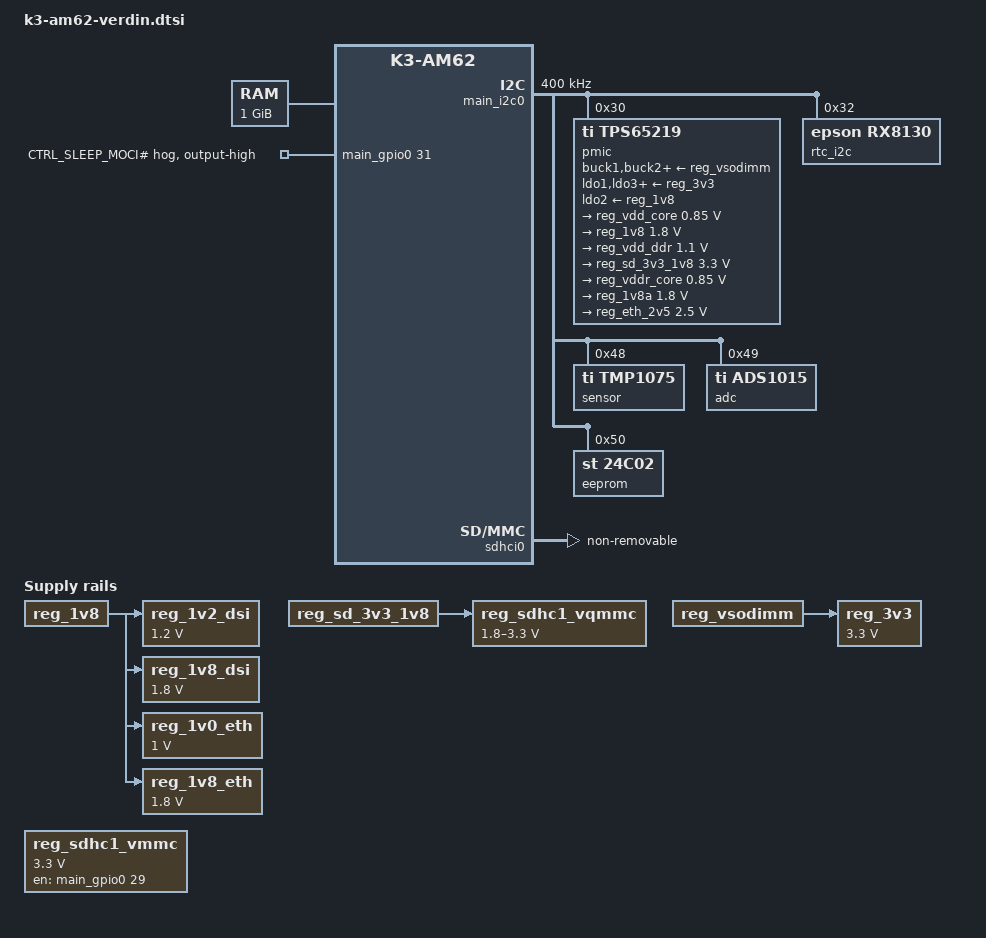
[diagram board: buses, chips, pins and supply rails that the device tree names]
#include <dt-bindings/gpio/gpio.h>
#include <dt-bindings/input/input.h>
#include <dt-bindings/interrupt-controller/arm-gic.h>
#include <dt-bindings/interrupt-controller/irq.h>
#include <dt-bindings/net/ti-dp83867.h>
/ {
	chosen {
		stdout-path = "serial2:115200n8";
	};
	aliases {
		can0 = &main_mcan0;
		can1 = &mcu_mcan0;
		ethernet0 = &cpsw_port1;
		ethernet1 = &cpsw_port2;
		i2c0 = &main_i2c0;
		i2c1 = &main_i2c1;
		i2c2 = &main_i2c2;
		i2c3 = &mcu_i2c0;
		i2c4 = &main_i2c3;
		mmc0 = &sdhci0;
		mmc1 = &sdhci1;
		mmc2 = &sdhci2;
		rtc0 = &rtc_i2c;
		rtc1 = &wkup_rtc0;
		serial0 = &main_uart1;
		serial1 = &wkup_uart0;
		serial2 = &main_uart0;
		serial3 = &mcu_uart0;
		serial4 = &main_uart5;
		usb0 = &usb0;
		usb1 = &usb1;
	};
	verdin_gpio_keys: gpio-keys {
		compatible = "gpio-keys";
		pinctrl-names = "default";
		pinctrl-0 = <&pinctrl_ctrl_wake1_mico>;
		status = "disabled";
		verdin_key_wakeup: key-wakeup {
			debounce-interval = <10>;
			gpios = <&main_gpio0 32 GPIO_ACTIVE_LOW>;
			label = "Wake-Up";
			linux,code = <KEY_WAKEUP>;
			wakeup-source;
		};
	};
	memory@80000000 {
		device_type = "memory";
		reg = <0x00000000 0x80000000 0x00000000 0x40000000>;  
	};
	opp-table {
		opp-1400000000 {
			opp-hz = /bits/ 64 <1400000000>;
			opp-supported-hw = <0x01 0x0004>;
			clock-latency-ns = <6000000>;
		};
	};
	reg_vsodimm: regulator-vsodimm {
		compatible = "regulator-fixed";
		regulator-name = "+V_SODIMM";
	};
	reg_3v3: regulator-3v3 {
		compatible = "regulator-fixed";
		regulator-max-microvolt = <3300000>;
		regulator-min-microvolt = <3300000>;
		regulator-name = "On-module +V3.3";
		vin-supply = <&reg_vsodimm>;
	};
	reg_1v2_dsi: regulator-1v2-dsi {
		compatible = "regulator-fixed";
		regulator-max-microvolt = <1200000>;
		regulator-min-microvolt = <1200000>;
		regulator-name = "On-module +V1.2_DSI";
		vin-supply = <&reg_1v8>;
	};
	reg_1v8_dsi: regulator-1v8-dsi {
		compatible = "regulator-fixed";
		regulator-max-microvolt = <1800000>;
		regulator-min-microvolt = <1800000>;
		regulator-name = "On-module +V1.8_DSI";
		vin-supply = <&reg_1v8>;
	};
	reg_1v0_eth: regulator-1v0-eth {
		compatible = "regulator-fixed";
		regulator-max-microvolt = <1000000>;
		regulator-min-microvolt = <1000000>;
		regulator-name = "On-module +V1.0_ETH";
		vin-supply = <&reg_1v8>;
	};
	reg_1v8_eth: regulator-1v8-eth {
		compatible = "regulator-fixed";
		regulator-max-microvolt = <1800000>;
		regulator-min-microvolt = <1800000>;
		regulator-name = "On-module +V1.8_ETH";
		vin-supply = <&reg_1v8>;
	};
	reg_sdhc1_vmmc: regulator-sdhci1 {
		compatible = "regulator-fixed";
		pinctrl-names = "default";
		pinctrl-0 = <&pinctrl_sd1_pwr_en>;
		enable-active-high;
		gpio = <&main_gpio0 29 GPIO_ACTIVE_HIGH>;
		off-on-delay-us = <100000>;
		regulator-max-microvolt = <3300000>;
		regulator-min-microvolt = <3300000>;
		regulator-name = "+V3.3_SD";
		startup-delay-us = <2000>;
	};
	reg_sdhc1_vqmmc: regulator-sdhci1-vqmmc {
		compatible = "regulator-gpio";
		pinctrl-names = "default";
		pinctrl-0 = <&pinctrl_vsel_sd>;
		gpios = <&main_gpio0 21 GPIO_ACTIVE_HIGH>;
		regulator-name = "LDO1-VSEL-SD (PMIC)";
		regulator-min-microvolt = <1800000>;
		regulator-max-microvolt = <3300000>;
		states = <1800000 0x0>,
			 <3300000 0x1>;
		vin-supply = <&reg_sd_3v3_1v8>;
	};
	reserved-memory {
		#address-cells = <2>;
		#size-cells = <2>;
		ranges;
		secure_tfa_ddr: tfa@9e780000 {
			reg = <0x00 0x9e780000 0x00 0x80000>;
			alignment = <0x1000>;
			no-map;
		};
		secure_ddr: optee@9e800000 {
			reg = <0x00 0x9e800000 0x00 0x01800000>;  
			alignment = <0x1000>;
			no-map;
		};
		wkup_r5fss0_core0_dma_memory_region: r5f-dma-memory@9db00000 {
			compatible = "shared-dma-pool";
			reg = <0x00 0x9db00000 0x00 0xc00000>;
			no-map;
		};
	};
};
&main_pmx0 {
	pinctrl_epwm0_a: main-epwm0a-default-pins {
		pinctrl-single,pins = <
			AM62X_IOPAD(0x01b4, PIN_OUTPUT, 2)    
		>;
	};
	pinctrl_epwm0_b: main-epwm0b-default-pins {
		pinctrl-single,pins = <
			AM62X_IOPAD(0x01b8, PIN_OUTPUT, 2)    
		>;
	};
	pinctrl_epwm1_a: main-epwm1a-default-pins {
		pinctrl-single,pins = <
			AM62X_IOPAD(0x01bc, PIN_OUTPUT, 2)    
		>;
	};
	pinctrl_qspi1_clk_gpio: main-gpio0-0-default-pins {
		pinctrl-single,pins = <
			AM62X_IOPAD(0x0000, PIN_INPUT, 7)    
		>;
	};
	pinctrl_qspi1_io0_gpio: main-gpio0-3-default-pins {
		pinctrl-single,pins = <
			AM62X_IOPAD(0x000c, PIN_INPUT, 7)    
		>;
	};
	pinctrl_qspi1_io1_gpio: main-gpio0-4-default-pins {
		pinctrl-single,pins = <
			AM62X_IOPAD(0x0010, PIN_INPUT, 7)    
		>;
	};
	pinctrl_qspi1_io2_gpio: main-gpio0-5-default-pins {
		pinctrl-single,pins = <
			AM62X_IOPAD(0x0014, PIN_INPUT, 7)    
		>;
	};
	pinctrl_qspi1_io3_gpio: main-gpio0-6-default-pins {
		pinctrl-single,pins = <
			AM62X_IOPAD(0x0018, PIN_INPUT, 7)    
		>;
	};
	pinctrl_qspi1_cs_gpio: main-gpio0-11-default-pins {
		pinctrl-single,pins = <
			AM62X_IOPAD(0x002c, PIN_INPUT, 7)    
		>;
	};
	pinctrl_qspi1_cs2_gpio: main-gpio0-12-default-pins {
		pinctrl-single,pins = <
			AM62X_IOPAD(0x0030, PIN_INPUT, 7)    
		>;
	};
	pinctrl_wifi_w_wkup_host: main-gpio0-15-default-pins {
		pinctrl-single,pins = <
			AM62X_IOPAD(0x003c, PIN_INPUT, 7)    
		>;
	};
	pinctrl_bt_wkup_host: main-gpio0-16-default-pins {
		pinctrl-single,pins = <
			AM62X_IOPAD(0x0040, PIN_INPUT, 7)    
		>;
	};
	pinctrl_eth_reset: main-gpio0-17-default-pins {
		pinctrl-single,pins = <
			AM62X_IOPAD(0x0044, PIN_INPUT, 7)  
		>;
	};
	pinctrl_bridge_reset: main-gpio0-20-default-pins {
		pinctrl-single,pins = <
			AM62X_IOPAD(0x0050, PIN_INPUT, 7)  
		>;
	};
	pinctrl_vsel_sd: main-gpio0-21-default-pins {
		pinctrl-single,pins = <
			AM62X_IOPAD(0x0054, PIN_INPUT, 7)  
		>;
	};
	pinctrl_wifi_en: main-gpio0-22-default-pins {
		pinctrl-single,pins = <
			AM62X_IOPAD(0x0058, PIN_INPUT, 7)  
		>;
	};
	pinctrl_eth_int: main-gpio0-25-default-pins {
		pinctrl-single,pins = <
			AM62X_IOPAD(0x0064, PIN_INPUT_PULLUP, 7)  
		>;
	};
	pinctrl_wifi_wkup_bt: main-gpio0-26-default-pins {
		pinctrl-single,pins = <
			AM62X_IOPAD(0x0068, PIN_INPUT, 7)  
		>;
	};
	pinctrl_wifi_wkup_wlan: main-gpio0-27-default-pins {
		pinctrl-single,pins = <
			AM62X_IOPAD(0x006c, PIN_INPUT, 7)  
		>;
	};
	pinctrl_sd1_pwr_en: main-gpio0-29-default-pins {
		pinctrl-single,pins = <
			AM62X_IOPAD(0x0074, PIN_INPUT, 7)    
		>;
	};
	pinctrl_dsi1_bkl_en: main-gpio0-30-default-pins {
		pinctrl-single,pins = <
			AM62X_IOPAD(0x0078, PIN_INPUT, 7)    
		>;
	};
	pinctrl_ctrl_sleep_moci: main-gpio0-31-default-pins {
		pinctrl-single,pins = <
			AM62X_IOPAD(0x007c, PIN_INPUT, 7)    
		>;
	};
	pinctrl_ctrl_wake1_mico: main-gpio0-32-default-pins {
		pinctrl-single,pins = <
			AM62X_IOPAD(0x0084, PIN_INPUT_PULLUP, 7)    
		>;
	};
	pinctrl_i2s_2_d_out_gpio: main-gpio0-34-default-pins {
		pinctrl-single,pins = <
			AM62X_IOPAD(0x008c, PIN_INPUT, 7)    
		>;
	};
	pinctrl_i2s_2_bclk_gpio: main-gpio0-35-default-pins {
		pinctrl-single,pins = <
			AM62X_IOPAD(0x0090, PIN_INPUT, 7)    
		>;
	};
	pinctrl_gpio_6: main-gpio0-36-default-pins {
		pinctrl-single,pins = <
			AM62X_IOPAD(0x0094, PIN_INPUT, 7)    
		>;
	};
	pinctrl_eth2_rgmii_int: main-gpio0-38-default-pins {
		pinctrl-single,pins = <
			AM62X_IOPAD(0x009c, PIN_INPUT, 7)    
		>;
	};
	pinctrl_gpio_5: main-gpio0-40-default-pins {
		pinctrl-single,pins = <
			AM62X_IOPAD(0x00a4, PIN_INPUT, 7)    
		>;
	};
	pinctrl_gpio_7: main-gpio0-41-default-pins {
		pinctrl-single,pins = <
			AM62X_IOPAD(0x00a8, PIN_INPUT, 7)    
		>;
	};
	pinctrl_gpio_8: main-gpio0-42-default-pins {
		pinctrl-single,pins = <
			AM62X_IOPAD(0x00ac, PIN_INPUT, 7)    
		>;
	};
	pinctrl_usb1_oc: main-gpio0-71-default-pins {
		pinctrl-single,pins = <
			AM62X_IOPAD(0x0124, PIN_INPUT, 7)    
		>;
	};
	pinctrl_usb2_oc: main-gpio0-72-default-pins {
		pinctrl-single,pins = <
			AM62X_IOPAD(0x0128, PIN_INPUT, 7)    
		>;
	};
	pinctrl_pwm3_dsi_gpio: main-gpio1-17-default-pins {
		pinctrl-single,pins = <
			AM62X_IOPAD(0x01bc, PIN_INPUT, 7)    
		>;
	};
	pinctrl_qspi1_dqs_gpio: main-gpio1-18-default-pins {
		pinctrl-single,pins = <
			AM62X_IOPAD(0x01c0, PIN_INPUT, 7)    
		>;
	};
	pinctrl_usb0_id: main-gpio1-19-default-pins {
		pinctrl-single,pins = <
			AM62X_IOPAD(0x01c4, PIN_INPUT, 7)    
		>;
	};
	pinctrl_dsi1_int: main-gpio1-49-default-pins {
		pinctrl-single,pins = <
			AM62X_IOPAD(0x0244, PIN_INPUT_PULLUP, 7)    
		>;
	};
	pinctrl_i2c0: main-i2c0-default-pins {
		pinctrl-single,pins = <
			AM62X_IOPAD(0x01e0, PIN_INPUT, 0)    
			AM62X_IOPAD(0x01e4, PIN_INPUT, 0)    
		>;
	};
	pinctrl_i2c1: main-i2c1-default-pins {
		pinctrl-single,pins = <
			AM62X_IOPAD(0x01e8, PIN_INPUT_PULLUP, 0)    
			AM62X_IOPAD(0x01ec, PIN_INPUT_PULLUP, 0)    
		>;
	};
	pinctrl_i2c2: main-i2c2-default-pins {
		pinctrl-single,pins = <
			AM62X_IOPAD(0x00b0, PIN_INPUT, 1)    
			AM62X_IOPAD(0x00b4, PIN_INPUT, 1)    
		>;
	};
	pinctrl_i2c3: main-i2c3-default-pins {
		pinctrl-single,pins = <
			AM62X_IOPAD(0x01d0, PIN_INPUT, 2)    
			AM62X_IOPAD(0x01d4, PIN_INPUT, 2)    
		>;
	};
	pinctrl_i2s1_mclk: main-system-audio-ext-reflock1-default-pins {
		pinctrl-single,pins = <
			AM62X_IOPAD(0x00a0, PIN_OUTPUT, 1)    
		>;
	};
	pinctrl_mcasp0: main-mcasp0-default-pins {
		pinctrl-single,pins = <
			AM62X_IOPAD(0x01a4, PIN_INPUT,  0)    
			AM62X_IOPAD(0x01a8, PIN_INPUT,  0)    
			AM62X_IOPAD(0x01a0, PIN_OUTPUT, 0)    
			AM62X_IOPAD(0x019c, PIN_INPUT,  0)    
		>;
	};
	pinctrl_mcasp1: main-mcasp1-default-pins {
		pinctrl-single,pins = <
			AM62X_IOPAD(0x0090, PIN_INPUT,  2)    
			AM62X_IOPAD(0x0098, PIN_INPUT,  2)    
			AM62X_IOPAD(0x008c, PIN_OUTPUT, 2)    
			AM62X_IOPAD(0x0088, PIN_INPUT,  2)    
		>;
	};
	pinctrl_mcan0: main-mcan0-default-pins {
		pinctrl-single,pins = <
			AM62X_IOPAD(0x01dc, PIN_INPUT,  0)    
			AM62X_IOPAD(0x01d8, PIN_OUTPUT, 0)    
		>;
	};
	pinctrl_mdio: main-mdio1-default-pins {
		pinctrl-single,pins = <
			AM62X_IOPAD(0x160, PIN_OUTPUT, 0)    
			AM62X_IOPAD(0x15c, PIN_INPUT, 0)     
		>;
	};
	pinctrl_sdhci0: main-mmc0-default-pins {
		pinctrl-single,pins = <
			AM62X_IOPAD(0x220, PIN_INPUT, 0)  
			AM62X_IOPAD(0x218, PIN_INPUT, 0)  
			AM62X_IOPAD(0x214, PIN_INPUT, 0)  
			AM62X_IOPAD(0x210, PIN_INPUT, 0)  
			AM62X_IOPAD(0x20c, PIN_INPUT, 0)  
			AM62X_IOPAD(0x208, PIN_INPUT, 0)  
			AM62X_IOPAD(0x204, PIN_INPUT, 0)  
			AM62X_IOPAD(0x200, PIN_INPUT, 0)  
			AM62X_IOPAD(0x1fc, PIN_INPUT, 0)  
			AM62X_IOPAD(0x1f8, PIN_INPUT, 0)  
		>;
	};
	pinctrl_sdhci1: main-mmc1-default-pins {
		pinctrl-single,pins = <
			AM62X_IOPAD(0x23c, PIN_INPUT,        0)    
			AM62X_IOPAD(0x234, PIN_INPUT,        0)    
			AM62X_IOPAD(0x230, PIN_INPUT,        0)    
			AM62X_IOPAD(0x22c, PIN_INPUT,        0)    
			AM62X_IOPAD(0x228, PIN_INPUT,        0)    
			AM62X_IOPAD(0x224, PIN_INPUT,        0)    
			AM62X_IOPAD(0x240, PIN_INPUT_PULLUP, 0)    
		>;
	};
	pinctrl_sdhci2: main-mmc2-default-pins {
		pinctrl-single,pins = <
			AM62X_IOPAD(0x120, PIN_INPUT, 0)    
			AM62X_IOPAD(0x118, PIN_INPUT, 0)    
			AM62X_IOPAD(0x114, PIN_INPUT, 0)    
			AM62X_IOPAD(0x110, PIN_INPUT, 0)    
			AM62X_IOPAD(0x10c, PIN_INPUT, 0)    
			AM62X_IOPAD(0x108, PIN_INPUT, 0)    
			AM62X_IOPAD(0x11c, PIN_INPUT, 0)  
		>;
	};
	pinctrl_ospi0: main-ospi0-default-pins {
		pinctrl-single,pins = <
			AM62X_IOPAD(0x0000, PIN_OUTPUT, 0)    
			AM62X_IOPAD(0x002c, PIN_OUTPUT, 0)    
			AM62X_IOPAD(0x0030, PIN_OUTPUT, 0)    
			AM62X_IOPAD(0x000c, PIN_INPUT, 0)     
			AM62X_IOPAD(0x0010, PIN_INPUT, 0)     
			AM62X_IOPAD(0x0014, PIN_INPUT, 0)     
			AM62X_IOPAD(0x0018, PIN_INPUT, 0)     
		>;
	};
	pinctrl_rgmii1: main-rgmii1-default-pins {
		pinctrl-single,pins = <
			AM62X_IOPAD(0x14c, PIN_INPUT,  0)  
			AM62X_IOPAD(0x150, PIN_INPUT,  0)  
			AM62X_IOPAD(0x154, PIN_INPUT,  0)  
			AM62X_IOPAD(0x158, PIN_INPUT,  0)  
			AM62X_IOPAD(0x148, PIN_INPUT,  0)  
			AM62X_IOPAD(0x144, PIN_INPUT,  0)  
			AM62X_IOPAD(0x134, PIN_OUTPUT, 0)  
			AM62X_IOPAD(0x138, PIN_OUTPUT, 0)  
			AM62X_IOPAD(0x13c, PIN_OUTPUT, 0)  
			AM62X_IOPAD(0x140, PIN_OUTPUT, 0)  
			AM62X_IOPAD(0x130, PIN_OUTPUT, 0)  
			AM62X_IOPAD(0x12c, PIN_OUTPUT, 0)  
		>;
	};
	pinctrl_rgmii2: main-rgmii2-default-pins {
		pinctrl-single,pins = <
			AM62X_IOPAD(0x184, PIN_INPUT,  0)    
			AM62X_IOPAD(0x188, PIN_INPUT,  0)    
			AM62X_IOPAD(0x18c, PIN_INPUT,  0)    
			AM62X_IOPAD(0x190, PIN_INPUT,  0)    
			AM62X_IOPAD(0x180, PIN_INPUT,  0)    
			AM62X_IOPAD(0x17c, PIN_INPUT,  0)    
			AM62X_IOPAD(0x16c, PIN_OUTPUT, 0)    
			AM62X_IOPAD(0x170, PIN_OUTPUT, 0)    
			AM62X_IOPAD(0x174, PIN_OUTPUT, 0)    
			AM62X_IOPAD(0x178, PIN_OUTPUT, 0)    
			AM62X_IOPAD(0x168, PIN_OUTPUT, 0)    
			AM62X_IOPAD(0x164, PIN_OUTPUT, 0)    
		>;
	};
	pinctrl_spi1: main-spi1-default-pins {
		pinctrl-single,pins = <
			AM62X_IOPAD(0x0020, PIN_INPUT, 1)    
			AM62X_IOPAD(0x001c, PIN_INPUT, 1)    
			AM62X_IOPAD(0x0024, PIN_INPUT, 1)    
			AM62X_IOPAD(0x0028, PIN_INPUT, 1)    
		>;
	};
	pinctrl_eth_clock: main-system-clkout0-default-pins {
		pinctrl-single,pins = <
			AM62X_IOPAD(0x01f0, PIN_OUTPUT_PULLUP, 5)  
		>;
	};
	pinctrl_pmic_extint: main-system-extint-default-pins {
		pinctrl-single,pins = <
			AM62X_IOPAD(0x01f4, PIN_INPUT, 0)  
		>;
	};
	pinctrl_uart0: main-uart0-default-pins {
		pinctrl-single,pins = <
			AM62X_IOPAD(0x1c8, PIN_INPUT_PULLUP, 0)    
			AM62X_IOPAD(0x1cc, PIN_OUTPUT,       0)    
		>;
	};
	pinctrl_uart1: main-uart1-default-pins {
		pinctrl-single,pins = <
			AM62X_IOPAD(0x0194, PIN_INPUT_PULLUP, 2)    
			AM62X_IOPAD(0x0198, PIN_OUTPUT,       2)    
			AM62X_IOPAD(0x01ac, PIN_INPUT_PULLUP, 2)    
			AM62X_IOPAD(0x01b0, PIN_OUTPUT,       2)    
		>;
	};
	pinctrl_uart5: main-uart5-default-pins {
		pinctrl-single,pins = <
			AM62X_IOPAD(0x0008, PIN_INPUT_PULLUP, 5)    
			AM62X_IOPAD(0x0004, PIN_OUTPUT,       5)    
			AM62X_IOPAD(0x0034, PIN_INPUT_PULLUP, 5)    
			AM62X_IOPAD(0x0038, PIN_OUTPUT,       5)    
		>;
	};
	pinctrl_usb0: main-usb0-default-pins {
		pinctrl-single,pins = <
			AM62X_IOPAD(0x0254, PIN_OUTPUT, 0)    
		>;
	};
	pinctrl_usb1: main-usb1-default-pins {
		pinctrl-single,pins = <
			AM62X_IOPAD(0x0258, PIN_OUTPUT, 0)    
		>;
	};
	pinctrl_parallel_rgb: main-vout-default-pins {
		pinctrl-single,pins = <
			AM62X_IOPAD(0x0100, PIN_OUTPUT, 0)  
			AM62X_IOPAD(0x00f8, PIN_OUTPUT, 0)  
			AM62X_IOPAD(0x0104, PIN_OUTPUT, 0)  
			AM62X_IOPAD(0x00fc, PIN_OUTPUT, 0)  
			AM62X_IOPAD(0x00b8, PIN_OUTPUT, 0)  
			AM62X_IOPAD(0x00bc, PIN_OUTPUT, 0)  
			AM62X_IOPAD(0x00c0, PIN_OUTPUT, 0)  
			AM62X_IOPAD(0x00c4, PIN_OUTPUT, 0)  
			AM62X_IOPAD(0x00c8, PIN_OUTPUT, 0)  
			AM62X_IOPAD(0x00cc, PIN_OUTPUT, 0)  
			AM62X_IOPAD(0x00d0, PIN_OUTPUT, 0)  
			AM62X_IOPAD(0x00d4, PIN_OUTPUT, 0)  
			AM62X_IOPAD(0x00d8, PIN_OUTPUT, 0)  
			AM62X_IOPAD(0x00dc, PIN_OUTPUT, 0)  
			AM62X_IOPAD(0x00e0, PIN_OUTPUT, 0)  
			AM62X_IOPAD(0x00e4, PIN_OUTPUT, 0)  
			AM62X_IOPAD(0x00e8, PIN_OUTPUT, 0)  
			AM62X_IOPAD(0x00ec, PIN_OUTPUT, 0)  
			AM62X_IOPAD(0x00f0, PIN_OUTPUT, 0)  
			AM62X_IOPAD(0x00f4, PIN_OUTPUT, 0)  
			AM62X_IOPAD(0x005c, PIN_OUTPUT, 1)  
			AM62X_IOPAD(0x0060, PIN_OUTPUT, 1)  
		>;
	};
};
&mcu_pmx0 {
	pinctrl_pcie_1_reset: mcu-gpio0-0-default-pins {
		pinctrl-single,pins = <
			AM62X_MCU_IOPAD(0x0000, PIN_INPUT, 7)    
		>;
	};
	pinctrl_gpio_1: mcu-gpio0-1-default-pins {
		pinctrl-single,pins = <
			AM62X_MCU_IOPAD(0x0004, PIN_INPUT, 7)    
		>;
	};
	pinctrl_gpio_2: mcu-gpio0-2-default-pins {
		pinctrl-single,pins = <
			AM62X_MCU_IOPAD(0x0008, PIN_INPUT, 7)    
		>;
	};
	pinctrl_gpio_3: mcu-gpio0-3-default-pins {
		pinctrl-single,pins = <
			AM62X_MCU_IOPAD(0x000c, PIN_INPUT, 7)    
		>;
	};
	pinctrl_gpio_4: mcu-gpio0-4-default-pins {
		pinctrl-single,pins = <
			AM62X_MCU_IOPAD(0x0010, PIN_INPUT, 7)    
		>;
	};
	pinctrl_mcu_i2c0: mcu-i2c0-default-pins {
		pinctrl-single,pins = <
			AM62X_MCU_IOPAD(0x0044, PIN_INPUT, 0)    
			AM62X_MCU_IOPAD(0x0048, PIN_INPUT, 0)    
		>;
	};
	pinctrl_mcu_mcan0: mcu-mcan0-default-pins {
		pinctrl-single,pins = <
			AM62X_MCU_IOPAD(0x0038, PIN_INPUT,  0)    
			AM62X_MCU_IOPAD(0x0034, PIN_OUTPUT, 0)    
		>;
	};
	pinctrl_mcu_uart0: mcu-uart0-default-pins {
		pinctrl-single,pins = <
			AM62X_MCU_IOPAD(0x0014, PIN_INPUT_PULLUP, 0)    
			AM62X_MCU_IOPAD(0x0018, PIN_OUTPUT,       0)    
		>;
	};
	pinctrl_csi1_mclk: wkup-clkout0-default-pins {
		pinctrl-single,pins = <
			AM62X_MCU_IOPAD(0x0084, PIN_OUTPUT, 0)    
		>;
	};
	pinctrl_wkup_uart0: wkup-uart0-default-pins {
		pinctrl-single,pins = <
			AM62X_MCU_IOPAD(0x002c, PIN_INPUT_PULLUP, 0)    
			AM62X_MCU_IOPAD(0x0030, PIN_OUTPUT,       0)    
			AM62X_MCU_IOPAD(0x0024, PIN_INPUT_PULLUP, 0)    
			AM62X_MCU_IOPAD(0x0028, PIN_OUTPUT,       0)    
		>;
	};
};
&audio_refclk1 {
	assigned-clock-rates = <25000000>;
};
&cpsw3g {
	pinctrl-names = "default";
	pinctrl-0 = <&pinctrl_rgmii1>;
	status = "disabled";
};
&cpsw_port1 {
	phy-handle = <&cpsw3g_phy0>;
	phy-mode = "rgmii-rxid";
	status = "disabled";
};
&cpsw_port2 {
	status = "disabled";
};
&cpsw3g_mdio {
	assigned-clocks = <&k3_clks 157 20>;
	assigned-clock-parents = <&k3_clks 157 22>;
	assigned-clock-rates = <25000000>;
	pinctrl-names = "default";
	pinctrl-0 = <&pinctrl_eth_clock>, <&pinctrl_mdio>;
	status = "disabled";
	cpsw3g_phy0: ethernet-phy@0 {
		compatible = "ethernet-phy-id2000.a231";
		reg = <0>;
		interrupt-parent = <&main_gpio0>;
		interrupts = <25 IRQ_TYPE_EDGE_FALLING>;
		pinctrl-names = "default";
		pinctrl-0 = <&pinctrl_eth_int>, <&pinctrl_eth_reset>;
		reset-gpios = <&main_gpio0 17 GPIO_ACTIVE_LOW>;
		reset-assert-us = <10>;
		reset-deassert-us = <1000>;
		ti,fifo-depth = <DP83867_PHYCR_FIFO_DEPTH_4_B_NIB>;
		ti,rx-internal-delay = <DP83867_RGMIIDCTL_2_00_NS>;
	};
};
&dss {
	pinctrl-names = "default";
	pinctrl-0 = <&pinctrl_parallel_rgb>;
	status = "disabled";
};
&dss_ports {
	#address-cells = <1>;
	#size-cells = <0>;
	port@1 {
		reg = <1>;
		dpi_out: endpoint {
			remote-endpoint = <&rgb_in>;
		};
	};
};
&epwm0 {
	pinctrl-names = "default";
	pinctrl-0 = <&pinctrl_epwm0_a>, <&pinctrl_epwm0_b>;
	status = "disabled";
};
&epwm1 {
	pinctrl-names = "default";
	pinctrl-0 = <&pinctrl_epwm1_a>;
	status = "disabled";
};
&main_gpio0 {
	gpio-line-names =
		"SODIMM_52",  
		"",
		"",
		"SODIMM_56",
		"SODIMM_58",
		"SODIMM_60",
		"SODIMM_62",
		"",
		"",
		"",
		"",  
		"SODIMM_54",
		"SODIMM_64",
		"",
		"",
		"SODIMM_174",
		"SODIMM_172",
		"",
		"",
		"",
		"",  
		"",
		"",
		"",
		"",
		"",
		"",
		"",
		"",
		"SODIMM_76",
		"SODIMM_21",  
		"SODIMM_256",
		"SODIMM_252",
		"",
		"SODIMM_46",
		"SODIMM_42",
		"SODIMM_218",
		"",
		"SODIMM_189",
		"",
		"SODIMM_216",  
		"SODIMM_220",
		"SODIMM_222",
		"",
		"",
		"",
		"",
		"",
		"",
		"",
		"",  
		"",
		"",
		"",
		"",
		"",
		"",
		"",
		"",
		"",
		"",  
		"",
		"",
		"",
		"",
		"",
		"",
		"",
		"",
		"",
		"",  
		"SODIMM_157",
		"SODIMM_187",
		"",
		"",
		"",
		"",
		"",
		"",
		"",
		"",  
		"",
		"",
		"",
		"",
		"",
		"";
	verdin_ctrl_sleep_moci: ctrl-sleep-moci-hog {
		gpio-hog;
		gpios = <31 GPIO_ACTIVE_HIGH>;
		line-name = "CTRL_SLEEP_MOCI#";
		output-high;
	};
};
&main_gpio1 {
	gpio-line-names =
		"",  
		"",
		"",
		"",
		"",
		"",
		"",
		"",
		"",
		"",
		"",  
		"",
		"",
		"",
		"",
		"SODIMM_15",
		"SODIMM_16",
		"SODIMM_19",
		"SODIMM_66",
		"SODIMM_161",
		"",  
		"",
		"",
		"",
		"",
		"",
		"",
		"",
		"",
		"",
		"",  
		"",
		"",
		"",
		"",
		"",
		"",
		"",
		"",
		"",
		"",  
		"",
		"",
		"",
		"",
		"",
		"",
		"",
		"",
		"SODIMM_17",
		"",  
		"",
		"",
		"",
		"",
		"",
		"",
		"",
		"",
		"",
		"",  
		"",
		"",
		"",
		"",
		"",
		"",
		"",
		"",
		"",
		"",  
		"",
		"",
		"",
		"",
		"",
		"",
		"",
		"",
		"",
		"",  
		"",
		"",
		"",
		"",
		"",
		"",
		"";
};
&main_i2c0 {
	pinctrl-names = "default";
	pinctrl-0 = <&pinctrl_i2c0>;
	clock-frequency = <400000>;
	status = "okay";
	dsi_bridge: dsi@e {
		compatible = "toshiba,tc358778";
		reg = <0xe>;
		assigned-clocks = <&k3_clks 157 20>;
		assigned-clock-parents = <&k3_clks 157 22>;
		assigned-clock-rates = <25000000>;
		pinctrl-names = "default";
		pinctrl-0 = <&pinctrl_bridge_reset>;
		clocks = <&k3_clks 157 20>;
		clock-names = "refclk";
		reset-gpios = <&main_gpio0 20 GPIO_ACTIVE_LOW>;
		vddc-supply = <&reg_1v2_dsi>;
		vddmipi-supply = <&reg_1v2_dsi>;
		vddio-supply = <&reg_1v8_dsi>;
		status = "disabled";
		dsi_bridge_ports: ports {
			#address-cells = <1>;
			#size-cells = <0>;
			port@0 {
				reg = <0>;
				rgb_in: endpoint {
					data-lines = <18>;
					remote-endpoint = <&dpi_out>;
				};
			};
			port@1 {
				reg = <1>;
			};
		};
	};
	pmic@30 {
		compatible = "ti,tps65219";
		reg = <0x30>;
		pinctrl-names = "default";
		pinctrl-0 = <&pinctrl_pmic_extint>;
		interrupt-parent = <&gic500>;
		interrupts = <GIC_SPI 224 IRQ_TYPE_LEVEL_HIGH>;
		buck1-supply = <&reg_vsodimm>;
		buck2-supply = <&reg_vsodimm>;
		buck3-supply = <&reg_vsodimm>;
		ldo1-supply = <&reg_3v3>;
		ldo2-supply = <&reg_1v8>;
		ldo3-supply = <&reg_3v3>;
		ldo4-supply = <&reg_3v3>;
		system-power-controller;
		ti,power-button;
		regulators {
			reg_vdd_core: buck1 {
				regulator-always-on;
				regulator-boot-on;
				regulator-max-microvolt = <850000>;
				regulator-min-microvolt = <850000>;
				regulator-name = "+VDD_CORE (PMIC BUCK1)";
			};
			reg_1v8: buck2 {
				regulator-always-on;
				regulator-boot-on;
				regulator-max-microvolt = <1800000>;
				regulator-min-microvolt = <1800000>;
				regulator-name = "+V1.8 (PMIC BUCK2)";  
			};
			reg_vdd_ddr: buck3 {
				regulator-always-on;
				regulator-boot-on;
				regulator-max-microvolt = <1100000>;
				regulator-min-microvolt = <1100000>;
				regulator-name = "+VDD_DDR (PMIC BUCK3)";
			};
			reg_sd_3v3_1v8: ldo1 {
				regulator-allow-bypass;
				regulator-always-on;
				regulator-boot-on;
				regulator-max-microvolt = <3300000>;
				regulator-min-microvolt = <3300000>;
				regulator-name = "+V3.3_1.8_SD (PMIC LDO1)";
			};
			reg_vddr_core: ldo2 {
				regulator-always-on;
				regulator-boot-on;
				regulator-max-microvolt = <850000>;
				regulator-min-microvolt = <850000>;
				regulator-name = "+VDDR_CORE (PMIC LDO2)";
			};
			reg_1v8a: ldo3 {
				regulator-always-on;
				regulator-boot-on;
				regulator-max-microvolt = <1800000>;
				regulator-min-microvolt = <1800000>;
				regulator-name = "+V1.8A (PMIC LDO3)";
			};
			reg_eth_2v5: ldo4 {
				regulator-always-on;
				regulator-boot-on;
				regulator-max-microvolt = <2500000>;
				regulator-min-microvolt = <2500000>;
				regulator-name = "+V2.5_ETH (PMIC LDO4)";
			};
		};
	};
	rtc_i2c: rtc@32 {
		compatible = "epson,rx8130";
		reg = <0x32>;
	};
	sensor@48 {
		compatible = "ti,tmp1075";
		reg = <0x48>;
	};
	adc@49 {
		compatible = "ti,ads1015";
		reg = <0x49>;
		#address-cells = <1>;
		#size-cells = <0>;
		channel@0 {
			reg = <0>;
			ti,datarate = <4>;
			ti,gain = <2>;
		};
		channel@1 {
			reg = <1>;
			ti,datarate = <4>;
			ti,gain = <2>;
		};
		channel@2 {
			reg = <2>;
			ti,datarate = <4>;
			ti,gain = <2>;
		};
		channel@3 {
			reg = <3>;
			ti,datarate = <4>;
			ti,gain = <2>;
		};
		channel@4 {
			reg = <4>;
			ti,datarate = <4>;
			ti,gain = <2>;
		};
		channel@5 {
			reg = <5>;
			ti,datarate = <4>;
			ti,gain = <2>;
		};
		channel@6 {
			reg = <6>;
			ti,datarate = <4>;
			ti,gain = <2>;
		};
		channel@7 {
			reg = <7>;
			ti,datarate = <4>;
			ti,gain = <2>;
		};
	};
	eeprom@50 {
		compatible = "st,24c02", "atmel,24c02";
		pagesize = <16>;
		reg = <0x50>;
	};
};
&main_i2c1 {
	pinctrl-names = "default";
	pinctrl-0 = <&pinctrl_i2c1>;
	status = "disabled";
};
&main_i2c2 {
	pinctrl-names = "default";
	pinctrl-0 = <&pinctrl_i2c2>;
	status = "disabled";
};
&main_i2c3 {
	pinctrl-names = "default";
	pinctrl-0 = <&pinctrl_i2c3>;
	status = "disabled";
};
&mailbox0_cluster0 {
	mbox_m4_0: mbox-m4-0 {
		ti,mbox-rx = <0 0 0>;
		ti,mbox-tx = <1 0 0>;
	};
};
&main_mcan0 {
	pinctrl-names = "default";
	pinctrl-0 = <&pinctrl_mcan0>;
	status = "disabled";
};
&main_spi1 {
	pinctrl-names = "default";
	pinctrl-0 = <&pinctrl_spi1>;
	ti,pindir-d0-out-d1-in;
	status = "disabled";
};
&main_uart0 {
	pinctrl-names = "default";
	pinctrl-0 = <&pinctrl_uart0>;
	status = "disabled";
};
&main_uart1 {
	pinctrl-names = "default";
	pinctrl-0 = <&pinctrl_uart1>;
	status = "disabled";
};
&mcasp0 {
	pinctrl-names = "default";
	pinctrl-0 = <&pinctrl_mcasp0>;
	op-mode = <0>;  
	serial-dir = <   
	       1 2 0 0
	       0 0 0 0
	       0 0 0 0
	       0 0 0 0
	>;
	tdm-slots = <2>;
	rx-num-evt = <32>;
	tx-num-evt = <32>;
	#sound-dai-cells = <0>;
	status = "disabled";
};
&mcasp1 {
	pinctrl-names = "default";
	pinctrl-0 = <&pinctrl_mcasp1>;
	op-mode = <0>;  
	serial-dir = <   
	       1 2 0 0
	       0 0 0 0
	       0 0 0 0
	       0 0 0 0
	>;
	tdm-slots = <2>;
	rx-num-evt = <32>;
	tx-num-evt = <32>;
	#sound-dai-cells = <0>;
	status = "disabled";
};
&mcu_i2c0 {
	pinctrl-names = "default";
	pinctrl-0 = <&pinctrl_mcu_i2c0>;
	status = "disabled";
};
&mcu_gpio0 {
	gpio-line-names =
		"SODIMM_244",
		"SODIMM_206",
		"SODIMM_208",
		"SODIMM_210",
		"SODIMM_212",
		"",
		"",
		"",
		"",
		"",
		"",
		"",
		"",
		"",
		"",
		"",
		"",
		"",
		"",
		"",
		"",
		"",
		"",
		"";
};
&mcu_mcan0 {
	pinctrl-names = "default";
	pinctrl-0 = <&pinctrl_mcu_mcan0>;
	status = "disabled";
};
&mcu_uart0 {
	pinctrl-names = "default";
	pinctrl-0 = <&pinctrl_mcu_uart0>;
	status = "disabled";
};
&ospi0 {
	pinctrl-names = "default";
	pinctrl-0 = <&pinctrl_ospi0>;
	status = "disabled";
};
&sdhci0 {
	pinctrl-names = "default";
	pinctrl-0 = <&pinctrl_sdhci0>;
	non-removable;
	ti,driver-strength-ohm = <50>;
	status = "okay";
};
&sdhci1 {
	pinctrl-names = "default";
	pinctrl-0 = <&pinctrl_sdhci1>;
	disable-wp;
	ti,driver-strength-ohm = <50>;
	vmmc-supply = <&reg_sdhc1_vmmc>;
	vqmmc-supply = <&reg_sdhc1_vqmmc>;
	status = "disabled";
};
&usbss0 {
	ti,vbus-divider;
	status = "disabled";
};
&usb0 {
	pinctrl-names = "default";
	pinctrl-0 = <&pinctrl_usb0>, <&pinctrl_usb0_id>;
	status = "disabled";
};
&usbss1 {
	ti,vbus-divider;
	status = "disabled";
};
&usb1 {
	pinctrl-names = "default";
	pinctrl-0 = <&pinctrl_usb1>;
	dr_mode = "host";
	status = "disabled";
};
&wkup_uart0 {
	pinctrl-names = "default";
	pinctrl-0 = <&pinctrl_wkup_uart0>;
	status = "disabled";
};
